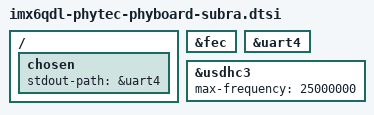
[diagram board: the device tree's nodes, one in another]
/*
 * Copyright (C) 2015 PHYTEC Messtechnik GmbH,
 * Author: Stefan Christ <s.christ@phytec.de>
 *
 * The code contained herein is licensed under the GNU General Public
 * License. You may obtain a copy of the GNU General Public License
 * Version 2 or later at the following locations:
 *
 * http://www.opensource.org/licenses/gpl-license.html
 * http://www.gnu.org/copyleft/gpl.html
 */

/ {
	chosen {
		stdout-path = &uart4;
	};
};

&fec {
	status = "okay";
};

&uart4 {
	status = "okay";
};

&usdhc3 {
	status = "okay";
	max-frequency = <25000000>; /* 25 Mhz */
};
